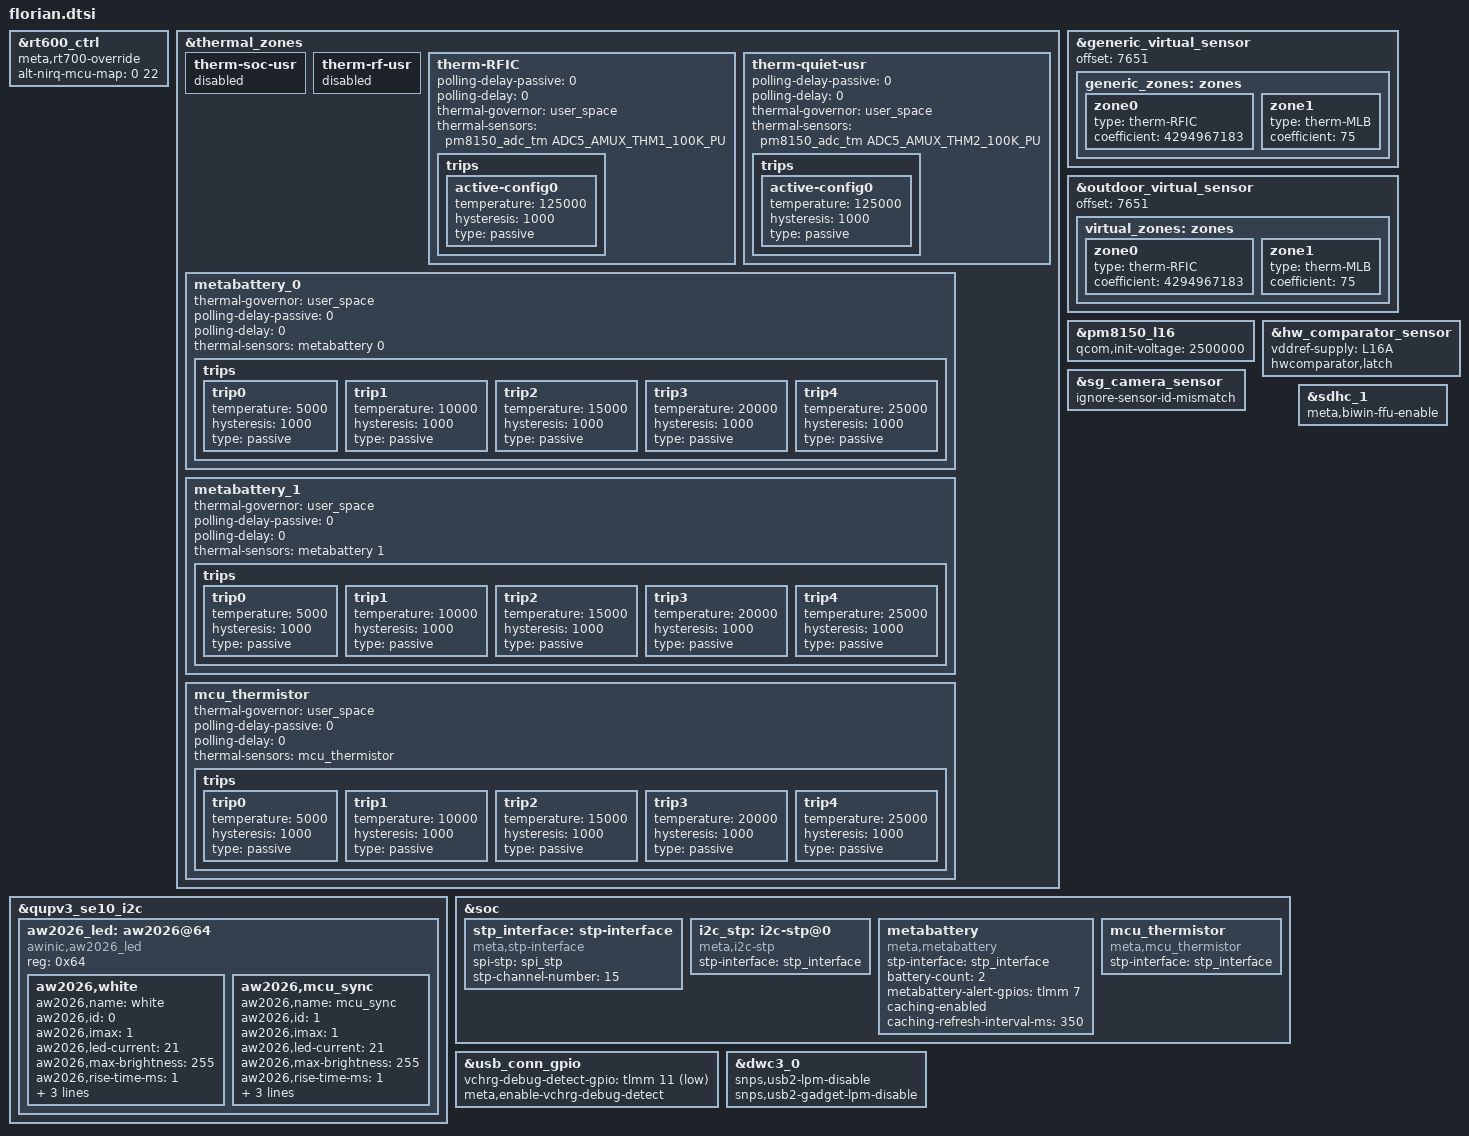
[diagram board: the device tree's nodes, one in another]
#include "meta-neo-common.dtsi"
#include "meta-neo-usb-conn-gpio.dtsi"
#include "florian-gpios.dtsi"
#include "meta-neo-camera-imx681-ao.dtsi"

&rt600_ctrl {
	meta,rt700-override;
	alt-nirq-mcu-map = <0 22>;
};

&thermal_zones {
	therm-soc-usr {
		status = "disabled";
	};
	therm-rf-usr{
		status = "disabled";
	};

	therm-RFIC {
		polling-delay-passive = <0>;
		polling-delay = <0>;
		thermal-governor = "user_space";
		thermal-sensors = <&pm8150_adc_tm ADC5_AMUX_THM1_100K_PU>;
		trips {
			active-config0 {
				temperature = <125000>;
				hysteresis = <1000>;
				type = "passive";
			};
		};
	};

	therm-quiet-usr {
		polling-delay-passive = <0>;
		polling-delay = <0>;
		thermal-governor = "user_space";
		thermal-sensors = <&pm8150_adc_tm ADC5_AMUX_THM2_100K_PU>;
		trips {
			active-config0 {
				temperature = <125000>;
				hysteresis = <1000>;
				type = "passive";
			};
		};
	};
	metabattery_0 {
		thermal-governor = "user_space";
		polling-delay-passive = <0>;
		polling-delay = <0>;
		thermal-sensors = <&metabattery 0>;
		trips {
			trip0 {
				temperature = <5000>;
				hysteresis = <1000>;
				type = "passive";
			};
			trip1 {
				temperature = <10000>;
				hysteresis = <1000>;
				type = "passive";
			};
			trip2 {
				temperature = <15000>;
				hysteresis = <1000>;
				type = "passive";
			};
			trip3 {
				temperature = <20000>;
				hysteresis = <1000>;
				type = "passive";
			};
			trip4 {
				temperature = <25000>;
				hysteresis = <1000>;
				type = "passive";
			};
		};
	};

	metabattery_1 {
		thermal-governor = "user_space";
		polling-delay-passive = <0>;
		polling-delay = <0>;
		thermal-sensors = <&metabattery 1>;
		trips {
			trip0 {
				temperature = <5000>;
				hysteresis = <1000>;
				type = "passive";
			};
			trip1 {
				temperature = <10000>;
				hysteresis = <1000>;
				type = "passive";
			};
			trip2 {
				temperature = <15000>;
				hysteresis = <1000>;
				type = "passive";
			};
			trip3 {
				temperature = <20000>;
				hysteresis = <1000>;
				type = "passive";
			};
			trip4 {
				temperature = <25000>;
				hysteresis = <1000>;
				type = "passive";
			};
		};
	};
	
	mcu_thermistor {
		thermal-governor = "user_space";
		polling-delay-passive = <0>;
		polling-delay = <0>;
		thermal-sensors = <&mcu_thermistor>;
		trips {
			trip0 {
				temperature = <5000>;
				hysteresis = <1000>;
				type = "passive";
			};
			trip1 {
				temperature = <10000>;
				hysteresis = <1000>;
				type = "passive";
			};
			trip2 {
				temperature = <15000>;
				hysteresis = <1000>;
				type = "passive";
			};
			trip3 {
				temperature = <20000>;
				hysteresis = <1000>;
				type = "passive";
			};
			trip4 {
				temperature = <25000>;
				hysteresis = <1000>;
				type = "passive";
			};
		};
	};
};

&generic_virtual_sensor {
	offset = <7651>;
	generic_zones: zones {
		zone0 {
			type = "therm-RFIC";
			// 32 bit 2's complement -113
			coefficient = <4294967183>;
		};
		zone1 {
			type = "therm-MLB";
			coefficient = <75>;
		};
	};
};

&outdoor_virtual_sensor {
	offset = <7651>;
	virtual_zones: zones {
		zone0 {
			type = "therm-RFIC";
			// 32 bit 2's complement -113
			coefficient = <4294967183>;
		};
		zone1 {
			type = "therm-MLB";
			coefficient = <75>;
		};
	};
};

&pm8150_l16 {
	qcom,init-voltage = <2500000>;
	/delete-property/ regulator-always-on;
};

&hw_comparator_sensor {
	vddref-supply = <&L16A>;
	hwcomparator,latch;
};

&qupv3_se10_i2c {
	aw2026_led: aw2026@64 {
		compatible = "awinic,aw2026_led";
		reg = <0x64>;
		status = "ok";

		aw2026,white {
			aw2026,name = "white";
			aw2026,id = <0>;
			aw2026,imax = <1>;
			aw2026,led-current = <21>;
			aw2026,max-brightness = <255>;
			aw2026,rise-time-ms = <1>;
			aw2026,hold-time-ms = <2>;
			aw2026,fall-time-ms = <4>;
			aw2026,off-time-ms = <1>;
		};

		aw2026,mcu_sync {
			aw2026,name = "mcu_sync";
			aw2026,id = <1>;
			aw2026,imax = <1>;
			aw2026,led-current = <21>;
			aw2026,max-brightness = <255>;
			aw2026,rise-time-ms = <1>;
			aw2026,hold-time-ms = <2>;
			aw2026,fall-time-ms = <4>;
			aw2026,off-time-ms = <1>;
    	};
	};
};

&sg_camera_sensor {
	ignore-sensor-id-mismatch;
};

&soc {
    stp_interface: stp-interface {
        status = "ok";
        compatible = "meta,stp-interface";
        spi-stp = <&spi_stp>;
		stp-channel-number = /bits/ 8 <15>;
    };

	i2c_stp: i2c-stp@0 {
		status = "ok";
		compatible = "meta,i2c-stp";
        stp-interface = <&stp_interface>;
	};

    metabattery: metabattery {
        compatible = "meta,metabattery";
        status = "ok";
        stp-interface = <&stp_interface>;
		battery-count = <2>;
		metabattery-alert-gpios = <&tlmm 7 GPIO_ACTIVE_HIGH>;
		#thermal-sensor-cells = <1>;
		caching-enabled;
		caching-refresh-interval-ms = <350>;
    };
	mcu_thermistor: mcu_thermistor {
        compatible = "meta,mcu_thermistor";
        status = "ok";
        stp-interface = <&stp_interface>;
		#thermal-sensor-cells = <0>;
    };
};

&usb_conn_gpio {
	vchrg-debug-detect-gpio = <&tlmm 11 GPIO_ACTIVE_LOW>;
	meta,enable-vchrg-debug-detect;
};

&dwc3_0 {
	snps,usb2-lpm-disable;
	snps,usb2-gadget-lpm-disable;
};

&sdhc_1 {
        meta,biwin-ffu-enable;
};
